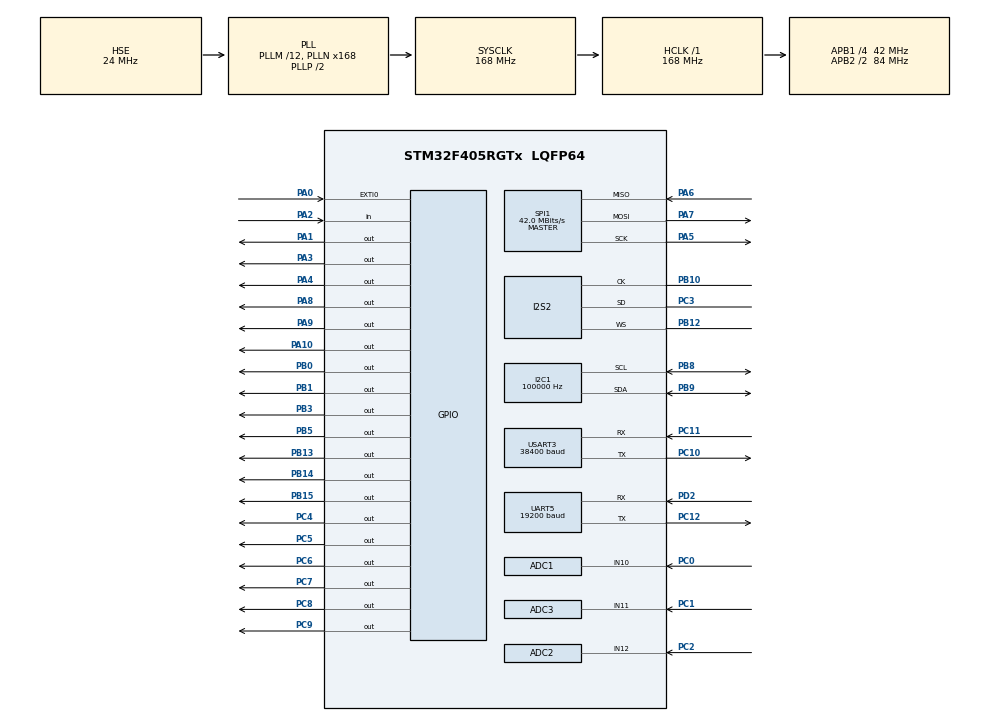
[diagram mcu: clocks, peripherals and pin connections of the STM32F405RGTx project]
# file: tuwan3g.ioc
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ADC1.Channel-0\#ChannelRegularConversion=ADC_CHANNEL_10
ADC1.ClockPrescaler=ADC_CLOCK_SYNC_PCLK_DIV4
ADC1.ContinuousConvMode=DISABLE
ADC1.DMAContinuousRequests=DISABLE
ADC1.DataAlign=ADC_DATAALIGN_RIGHT
ADC1.DiscontinuousConvMode=DISABLE
ADC1.EOCSelection=ADC_EOC_SINGLE_CONV
ADC1.EnableAnalogWatchDog=false
ADC1.ExternalTrigConvEdge=ADC_EXTERNALTRIGCONVEDGE_NONE
ADC1.InjNumberOfConversion=0
ADC1.NbrOfConversion=1
ADC1.NbrOfConversionFlag=1
ADC1.Rank-0\#ChannelRegularConversion=1
ADC1.Resolution=ADC_RESOLUTION_12B
ADC1.SamplingTime-0\#ChannelRegularConversion=ADC_SAMPLETIME_3CYCLES
ADC1.ScanConvMode=DISABLE
ADC1.master=1
ADC2.Channel-0\#ChannelRegularConversion=ADC_CHANNEL_12
ADC2.NbrOfConversionFlag=1
ADC2.Rank-0\#ChannelRegularConversion=1
ADC2.SamplingTime-0\#ChannelRegularConversion=ADC_SAMPLETIME_3CYCLES
ADC3.Channel-0\#ChannelRegularConversion=ADC_CHANNEL_11
ADC3.NbrOfConversionFlag=1
ADC3.Rank-0\#ChannelRegularConversion=1
ADC3.SamplingTime-0\#ChannelRegularConversion=ADC_SAMPLETIME_3CYCLES
Dma.Request0=SPI2_RX
Dma.Request1=USART3_TX
Dma.Request2=UART5_TX
Dma.SPI2_RX.0.Direction=DMA_PERIPH_TO_MEMORY
Dma.SPI2_RX.0.FIFOMode=DMA_FIFOMODE_DISABLE
Dma.SPI2_RX.0.Instance=DMA1_Stream3
Dma.SPI2_RX.0.MemDataAlignment=DMA_MDATAALIGN_HALFWORD
Dma.SPI2_RX.0.MemInc=DMA_MINC_ENABLE
Dma.SPI2_RX.0.Mode=DMA_CIRCULAR
Dma.SPI2_RX.0.PeriphDataAlignment=DMA_PDATAALIGN_HALFWORD
Dma.SPI2_RX.0.PeriphInc=DMA_PINC_DISABLE
Dma.SPI2_RX.0.Priority=DMA_PRIORITY_LOW
Dma.UART5_TX.2.Direction=DMA_MEMORY_TO_PERIPH
Dma.UART5_TX.2.FIFOMode=DMA_FIFOMODE_DISABLE
Dma.UART5_TX.2.Instance=DMA1_Stream7
Dma.UART5_TX.2.MemDataAlignment=DMA_MDATAALIGN_BYTE
Dma.UART5_TX.2.MemInc=DMA_MINC_ENABLE
Dma.UART5_TX.2.Mode=DMA_NORMAL
Dma.UART5_TX.2.PeriphDataAlignment=DMA_PDATAALIGN_BYTE
Dma.UART5_TX.2.PeriphInc=DMA_PINC_DISABLE
Dma.UART5_TX.2.Priority=DMA_PRIORITY_LOW
Dma.USART3_TX.1.Direction=DMA_MEMORY_TO_PERIPH
Dma.USART3_TX.1.FIFOMode=DMA_FIFOMODE_DISABLE
Dma.USART3_TX.1.Instance=DMA1_Stream4
Dma.USART3_TX.1.MemDataAlignment=DMA_MDATAALIGN_BYTE
Dma.USART3_TX.1.MemInc=DMA_MINC_ENABLE
Dma.USART3_TX.1.Mode=DMA_NORMAL
Dma.USART3_TX.1.PeriphDataAlignment=DMA_PDATAALIGN_BYTE
Dma.USART3_TX.1.PeriphInc=DMA_PINC_DISABLE
Dma.USART3_TX.1.Priority=DMA_PRIORITY_LOW
FREERTOS.Queues01=UART5Q,50,unsigned char,NULL;UART3Q,300,uint8_t,NULL
FREERTOS.Tasks01=MainTask,2,1000,MainTaskFunction,As weak;ForthTemialTask,-2,128,ForthTemialFunction,As weak;PositionTask,0,500,PositionTaskFunction,As weak;ActionTask,1,512,ActionTaskFunction,As weak;SnoreTask,0,1000,SnoreTaskFunction,As weak
FREERTOS.configTICK_RATE_HZ=1000
I2C1.ClockSpeed=100000
I2S2.AudioFreq=I2S_AUDIOFREQ_32K
I2S2.CPOL=I2S_CPOL_LOW
I2S2.ErrorAudioFreq=0.8 %
I2S2.Mode=I2S_MODE_MASTER_RX
I2S2.RealAudioFreq=32.258 KHz
I2S2.Standard=I2S_STANDARD_LSB
Mcu.Family=STM32F4
Mcu.Name=STM32F405RGTx
Mcu.Package=LQFP64
NVIC.ADC_IRQn=true\:0\:0\:false\:false\:true\:false
NVIC.DMA1_Stream3_IRQn=true\:6\:0\:true\:false\:true\:false
NVIC.DMA1_Stream4_IRQn=true\:5\:0\:false\:false\:true\:true
NVIC.DMA1_Stream7_IRQn=true\:5\:0\:false\:false\:true\:true
NVIC.EXTI0_IRQn=true\:5\:0\:false\:false\:true\:true
NVIC.PriorityGroup=NVIC_PRIORITYGROUP_4
NVIC.SPI1_IRQn=true\:0\:0\:false\:false\:true\:false
NVIC.SPI2_IRQn=true\:0\:0\:false\:false\:true\:false
NVIC.TIM6_DAC_IRQn=true\:0\:0\:false\:false\:true\:false
NVIC.TimeBase=TIM6_DAC_IRQn
NVIC.TimeBaseIP=TIM6
NVIC.UART5_IRQn=true\:5\:0\:false\:false\:true\:true
NVIC.USART3_IRQn=true\:5\:0\:true\:false\:true\:true
PA0-WKUP.Signal=GPXTI0
PA1.Signal=GPIO_Output
PA10.Signal=GPIO_Output
PA13.Mode=Serial_Wire
PA13.Signal=SYS_JTMS-SWDIO
PA14.Mode=Serial_Wire
PA14.Signal=SYS_JTCK-SWCLK
PA2.Signal=GPIO_Input
PA3.Signal=GPIO_Output
PA4.GPIO_Speed=GPIO_SPEED_FREQ_VERY_HIGH
PA4.PinState=GPIO_PIN_SET
PA4.Signal=GPIO_Output
PA5.GPIO_PuPd=GPIO_PULLUP
PA5.GPIO_Speed=GPIO_SPEED_FREQ_HIGH
PA5.Mode=Full_Duplex_Master
PA5.Signal=SPI1_SCK
PA6.GPIO_PuPd=GPIO_PULLUP
PA6.GPIO_Speed=GPIO_SPEED_FREQ_HIGH
PA6.Mode=Full_Duplex_Master
PA6.Signal=SPI1_MISO
PA7.GPIO_PuPd=GPIO_PULLUP
PA7.GPIO_Speed=GPIO_SPEED_FREQ_HIGH
PA7.Mode=Full_Duplex_Master
PA7.Signal=SPI1_MOSI
PA8.Signal=GPIO_Output
PA9.Signal=GPIO_Output
PB0.Signal=GPIO_Output
PB1.Signal=GPIO_Output
PB10.Mode=Half_Duplex_Master
PB10.Signal=I2S2_CK
PB12.Mode=Half_Duplex_Master
PB12.Signal=I2S2_WS
PB13.Signal=GPIO_Output
PB14.Signal=GPIO_Output
PB15.Signal=GPIO_Output
PB3.Signal=GPIO_Output
PB5.Signal=GPIO_Output
PB8.Mode=I2C
PB8.Signal=I2C1_SCL
PB9.Mode=I2C
PB9.Signal=I2C1_SDA
PC0.Signal=ADCx_IN10
PC1.Signal=ADCx_IN11
PC10.Mode=Asynchronous
PC10.Signal=USART3_TX
PC11.Mode=Asynchronous
PC11.Signal=USART3_RX
PC12.GPIO_Mode=GPIO_MODE_AF_PP
PC12.Mode=Asynchronous
PC12.Signal=UART5_TX
PC14-OSC32_IN.Mode=LSE-External-Oscillator
PC14-OSC32_IN.Signal=RCC_OSC32_IN
PC15-OSC32_OUT.Mode=LSE-External-Oscillator
PC15-OSC32_OUT.Signal=RCC_OSC32_OUT
PC2.Signal=ADCx_IN12
PC3.Mode=Half_Duplex_Master
PC3.Signal=I2S2_SD
PC4.Signal=GPIO_Output
PC5.Signal=GPIO_Output
PC6.Signal=GPIO_Output
PC7.Signal=GPIO_Output
PC8.Signal=GPIO_Output
PC9.Signal=GPIO_Output
PD2.Mode=Asynchronous
PD2.Signal=UART5_RX
PH0-OSC_IN.Mode=HSE-External-Oscillator
PH0-OSC_IN.Signal=RCC_OSC_IN
PH1-OSC_OUT.Mode=HSE-External-Oscillator
PH1-OSC_OUT.Signal=RCC_OSC_OUT
ProjectManager.HeapSize=0x900
ProjectManager.StackSize=0x2000
ProjectManager.TargetToolchain=MDK-ARM V5
RCC.48MHZClocksFreq_Value=84000000
RCC.AHBFreq_Value=168000000
RCC.APB1CLKDivider=RCC_HCLK_DIV4
RCC.APB1Freq_Value=42000000
RCC.APB1TimFreq_Value=84000000
RCC.APB2CLKDivider=RCC_HCLK_DIV2
RCC.APB2Freq_Value=84000000
RCC.APB2TimFreq_Value=168000000
RCC.CortexFreq_Value=168000000
RCC.HCLKFreq_Value=168000000
RCC.HSE_VALUE=24000000
RCC.HSI_VALUE=16000000
RCC.PLLI2SN=96
RCC.PLLI2SR=6
RCC.PLLM=12
RCC.PLLN=168
RCC.PLLSourceVirtual=RCC_PLLSOURCE_HSE
RCC.RCC_RTC_Clock_SourceVirtual=RCC_RTCCLKSOURCE_LSE
RCC.SYSCLKFreq_VALUE=168000000
RCC.SYSCLKSource=RCC_SYSCLKSOURCE_PLLCLK
RCC.VCOOutputFreq_Value=336000000
RTC.Hours=8
RTC.Seconds=10
SH.ADCx_IN10.0=ADC1_IN10,IN10
SH.ADCx_IN11.0=ADC3_IN11,IN11
SH.ADCx_IN12.0=ADC2_IN12,IN12
SPI1.BaudRatePrescaler=SPI_BAUDRATEPRESCALER_2
SPI1.CLKPhase=SPI_PHASE_2EDGE
SPI1.CLKPolarity=SPI_POLARITY_HIGH
SPI1.CalculateBaudRate=42.0 MBits/s
SPI1.Mode=SPI_MODE_MASTER
UART5.BaudRate=19200
USART3.BaudRate=38400
VP_FREERTOS_VS_ENABLE.Mode=Enabled
VP_RTC_VS_RTC_WakeUp_intern.Mode=WakeUp
VP_SYS_VS_tim6.Mode=TIM6
board=tuwan3g

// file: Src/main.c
/**
  ******************************************************************************
  * File Name          : main.c
  * Description        : Main program body
  ******************************************************************************
  *
  * COPYRIGHT(c) 2017 STMicroelectronics
  *
  * Redistribution and use in source and binary forms, with or without modification,
  * are permitted provided that the following conditions are met:
  *   1. Redistributions of source code must retain the above copyright notice,
  *      this list of conditions and the following disclaimer.
  *   2. Redistributions in binary form must reproduce the above copyright notice,
  *      this list of conditions and the following disclaimer in the documentation
  *      and/or other materials provided with the distribution.
  *   3. Neither the name of STMicroelectronics nor the names of its contributors
  *      may be used to endorse or promote products derived from this software
  *      without specific prior written permission.
  *
  * THIS SOFTWARE IS PROVIDED BY THE COPYRIGHT HOLDERS AND CONTRIBUTORS "AS IS"
  * AND ANY EXPRESS OR IMPLIED WARRANTIES, INCLUDING, BUT NOT LIMITED TO, THE
  * IMPLIED WARRANTIES OF MERCHANTABILITY AND FITNESS FOR A PARTICULAR PURPOSE ARE
  * DISCLAIMED. IN NO EVENT SHALL THE COPYRIGHT HOLDER OR CONTRIBUTORS BE LIABLE
  * FOR ANY DIRECT, INDIRECT, INCIDENTAL, SPECIAL, EXEMPLARY, OR CONSEQUENTIAL
  * DAMAGES (INCLUDING, BUT NOT LIMITED TO, PROCUREMENT OF SUBSTITUTE GOODS OR
  * SERVICES; LOSS OF USE, DATA, OR PROFITS; OR BUSINESS INTERRUPTION) HOWEVER
  * CAUSED AND ON ANY THEORY OF LIABILITY, WHETHER IN CONTRACT, STRICT LIABILITY,
  * OR TORT (INCLUDING NEGLIGENCE OR OTHERWISE) ARISING IN ANY WAY OUT OF THE USE
  * OF THIS SOFTWARE, EVEN IF ADVISED OF THE POSSIBILITY OF SUCH DAMAGE.
  *
  ******************************************************************************
  */
#include "stm32f4xx_hal.h"
#include "cmsis_os.h"

/* USER CODE BEGIN Includes */
#include "W25Q16.h"
#include "tuwan.h"
/* USER CODE END Includes */

ADC_HandleTypeDef hadc1;
ADC_HandleTypeDef hadc2;
ADC_HandleTypeDef hadc3;

I2C_HandleTypeDef hi2c1;

I2S_HandleTypeDef hi2s2;
DMA_HandleTypeDef hdma_spi2_rx;

RTC_HandleTypeDef hrtc;

SPI_HandleTypeDef hspi1;

UART_HandleTypeDef huart5;
UART_HandleTypeDef huart3;
DMA_HandleTypeDef hdma_uart5_tx;
DMA_HandleTypeDef hdma_usart3_tx;

osThreadId MainTaskHandle;
osThreadId ForthTemialTaskHandle;
osThreadId PositionTaskHandle;
osThreadId ActionTaskHandle;
osThreadId SnoreTaskHandle;
osMessageQId UART5QHandle;
osMessageQId UART3QHandle;

/* USER CODE BEGIN PV */
xQueueHandle  ExhalAdcQHandle,InhalAdcQHandle;
/* Private variables ---------------------------------------------------------*/
/* USER CODE END PV */

void SystemClock_Config(void);
void Error_Handler(void);
static void MX_GPIO_Init(void);
static void MX_DMA_Init(void);
static void MX_I2C1_Init(void);
static void MX_I2S2_Init(void);
static void MX_SPI1_Init(void);
static void MX_UART5_Init(void);
static void MX_USART3_UART_Init(void);
static void MX_ADC1_Init(void);
static void MX_ADC2_Init(void);
static void MX_RTC_Init(void);
static void MX_ADC3_Init(void);
void MainTaskFunction(void const * argument);
void ForthTemialFunction(void const * argument);
void PositionTaskFunction(void const * argument);
void ActionTaskFunction(void const * argument);
void SnoreTaskFunction(void const * argument);

/* USER CODE BEGIN PFP */
/* Private function prototypes -----------------------------------------------*/

/* USER CODE END PFP */

int main(void)
{

  /* MCU Configuration----------------------------------------------------------*/

  /* Reset of all peripherals, Initializes the Flash interface and the Systick. */
  HAL_Init();

  /* Configure the system clock */
  SystemClock_Config();

  /* Initialize all configured peripherals */
  MX_GPIO_Init();
  MX_DMA_Init();
#ifndef SOFTIIC
  MX_I2C1_Init();
#endif
  MX_I2S2_Init();
  MX_SPI1_Init();
  MX_UART5_Init();
  MX_USART3_UART_Init();
  MX_ADC1_Init();
  MX_ADC2_Init();
  MX_RTC_Init();
  MX_ADC3_Init();

  /* USER CODE BEGIN 2 */
  FLASH_SPI_CS_DISABLE();
	__set_PRIMASK(0);
	//CheckSystemParameter(); //disabled by zjp for no bootloader
	InhalePump(0);
	ExhalePump(0);

	BlueToolthEnabled(0);
	ERP_ON();
	/// BlueToolLed(1);
	 ErrorCode=0;

	 PowerLed(1);
	 RunLed(1);
	 /*
	 ResetValuePump();

	 EntryStandbyMode();
	*/
  // while(1);

	 /*
	 while(1)
	 {
	 d=10000000;
	 PowerLed(0);
	 while(d--);
		  d=10000000;
	 PowerLed(1);
	 while(d--);

	 }
	 */

  /* USER CODE END 2 */

  /* Create the thread(s) */
  /* definition and creation of MainTask */
  osThreadDef(MainTask, MainTaskFunction, osPriorityNormal, 0, 1100);
  MainTaskHandle = osThreadCreate(osThread(MainTask), NULL);

  /* definition and creation of ForthTemialTask */
  osThreadDef(ForthTemialTask, ForthTemialFunction, osPriorityLow, 0, 128);
  ForthTemialTaskHandle = osThreadCreate(osThread(ForthTemialTask), NULL);

  /* definition and creation of PositionTask */
  osThreadDef(PositionTask, PositionTaskFunction, osPriorityBelowNormal, 0, 500);
  PositionTaskHandle = osThreadCreate(osThread(PositionTask), NULL);

  /* definition and creation of ActionTask */
  osThreadDef(ActionTask, ActionTaskFunction, osPriorityLow, 0, 512);
  ActionTaskHandle = osThreadCreate(osThread(ActionTask), NULL);

  /* definition and creation of SnoreTask */
  osThreadDef(SnoreTask, SnoreTaskFunction, osPriorityHigh, 0, 1000);
  SnoreTaskHandle = osThreadCreate(osThread(SnoreTask), NULL);

  /* Create the queue(s) */
  /* definition and creation of UART5Q */
  osMessageQDef(UART5Q, 50, unsigned char);
  UART5QHandle = osMessageCreate(osMessageQ(UART5Q), NULL);

  /* definition and creation of UART3Q */
  osMessageQDef(UART3Q, 300, uint8_t);
  UART3QHandle = osMessageCreate(osMessageQ(UART3Q), NULL);

  /* USER CODE BEGIN RTOS_QUEUES */
  /* add queues, ... */
  ExhalAdcQHandle = xQueueCreate( 10 , sizeof( unsigned int) );
	InhalAdcQHandle = xQueueCreate( 10 , sizeof( unsigned int) );
  /* USER CODE END RTOS_QUEUES */

  /* Start scheduler */
  osKernelStart();

  /* We should never get here as control is now taken by the scheduler */

  /* Infinite loop */
  while (1)
  {

  }

}

/** System Clock Configuration
*/
void SystemClock_Config(void)
{

  RCC_OscInitTypeDef RCC_OscInitStruct;
  RCC_ClkInitTypeDef RCC_ClkInitStruct;
  RCC_PeriphCLKInitTypeDef PeriphClkInitStruct;

  __HAL_RCC_PWR_CLK_ENABLE();

  __HAL_PWR_VOLTAGESCALING_CONFIG(PWR_REGULATOR_VOLTAGE_SCALE1);

  RCC_OscInitStruct.OscillatorType = RCC_OSCILLATORTYPE_HSE|RCC_OSCILLATORTYPE_LSE;
  RCC_OscInitStruct.HSEState = RCC_HSE_ON;
  RCC_OscInitStruct.LSEState = RCC_LSE_ON;
  RCC_OscInitStruct.PLL.PLLState = RCC_PLL_ON;
  RCC_OscInitStruct.PLL.PLLSource = RCC_PLLSOURCE_HSE;
  RCC_OscInitStruct.PLL.PLLM = 12;
  RCC_OscInitStruct.PLL.PLLN = 168;
  RCC_OscInitStruct.PLL.PLLP = RCC_PLLP_DIV2;
  RCC_OscInitStruct.PLL.PLLQ = 4;
  if (HAL_RCC_OscConfig(&RCC_OscInitStruct) != HAL_OK)
  {
    Error_Handler();
  }

  RCC_ClkInitStruct.ClockType = RCC_CLOCKTYPE_HCLK|RCC_CLOCKTYPE_SYSCLK
                              |RCC_CLOCKTYPE_PCLK1|RCC_CLOCKTYPE_PCLK2;
  RCC_ClkInitStruct.SYSCLKSource = RCC_SYSCLKSOURCE_PLLCLK;
  RCC_ClkInitStruct.AHBCLKDivider = RCC_SYSCLK_DIV1;
  RCC_ClkInitStruct.APB1CLKDivider = RCC_HCLK_DIV4;
  RCC_ClkInitStruct.APB2CLKDivider = RCC_HCLK_DIV2;
  if (HAL_RCC_ClockConfig(&RCC_ClkInitStruct, FLASH_LATENCY_5) != HAL_OK)
  {
    Error_Handler();
  }

  PeriphClkInitStruct.PeriphClockSelection = RCC_PERIPHCLK_I2S|RCC_PERIPHCLK_RTC;
  PeriphClkInitStruct.PLLI2S.PLLI2SN = 96;
  PeriphClkInitStruct.PLLI2S.PLLI2SR = 6;
  PeriphClkInitStruct.RTCClockSelection = RCC_RTCCLKSOURCE_LSE;
  if (HAL_RCCEx_PeriphCLKConfig(&PeriphClkInitStruct) != HAL_OK)
  {
    Error_Handler();
  }

  HAL_SYSTICK_Config(HAL_RCC_GetHCLKFreq()/1000);

  HAL_SYSTICK_CLKSourceConfig(SYSTICK_CLKSOURCE_HCLK);

  /* SysTick_IRQn interrupt configuration */
  HAL_NVIC_SetPriority(SysTick_IRQn, 15, 0);
}

/* ADC1 init function */
static void MX_ADC1_Init(void)
{

  ADC_ChannelConfTypeDef sConfig;

    /**Configure the global features of the ADC (Clock, Resolution, Data Alignment and number of conversion)
    */
  hadc1.Instance = ADC1;
  hadc1.Init.ClockPrescaler = ADC_CLOCK_SYNC_PCLK_DIV4;
  hadc1.Init.Resolution = ADC_RESOLUTION_12B;
  hadc1.Init.ScanConvMode = DISABLE;
  hadc1.Init.ContinuousConvMode = DISABLE;
  hadc1.Init.DiscontinuousConvMode = DISABLE;
  hadc1.Init.ExternalTrigConvEdge = ADC_EXTERNALTRIGCONVEDGE_NONE;
  hadc1.Init.DataAlign = ADC_DATAALIGN_RIGHT;
  hadc1.Init.NbrOfConversion = 1;
  hadc1.Init.DMAContinuousRequests = DISABLE;
  hadc1.Init.EOCSelection = ADC_EOC_SINGLE_CONV;
  if (HAL_ADC_Init(&hadc1) != HAL_OK)
  {
    Error_Handler();
  }

    /**Configure for the selected ADC regular channel its corresponding rank in the sequencer and its sample time.
    */
  sConfig.Channel = ADC_CHANNEL_10;
  sConfig.Rank = 1;
  sConfig.SamplingTime = ADC_SAMPLETIME_3CYCLES;
  if (HAL_ADC_ConfigChannel(&hadc1, &sConfig) != HAL_OK)
  {
    Error_Handler();
  }

}

/* ADC2 init function */
static void MX_ADC2_Init(void)
{

  ADC_ChannelConfTypeDef sConfig;

    /**Configure the global features of the ADC (Clock, Resolution, Data Alignment and number of conversion)
    */
  hadc2.Instance = ADC2;
  hadc2.Init.ClockPrescaler = ADC_CLOCK_SYNC_PCLK_DIV4;
  hadc2.Init.Resolution = ADC_RESOLUTION_12B;
  hadc2.Init.ScanConvMode = DISABLE;
  hadc2.Init.ContinuousConvMode = DISABLE;
  hadc2.Init.DiscontinuousConvMode = DISABLE;
  hadc2.Init.ExternalTrigConvEdge = ADC_EXTERNALTRIGCONVEDGE_NONE;
  hadc2.Init.DataAlign = ADC_DATAALIGN_RIGHT;
  hadc2.Init.NbrOfConversion = 1;
  hadc2.Init.DMAContinuousRequests = DISABLE;
  hadc2.Init.EOCSelection = ADC_EOC_SINGLE_CONV;
  if (HAL_ADC_Init(&hadc2) != HAL_OK)
  {
    Error_Handler();
  }

    /**Configure for the selected ADC regular channel its corresponding rank in the sequencer and its sample time.
    */
  sConfig.Channel = ADC_CHANNEL_12;
  sConfig.Rank = 1;
  sConfig.SamplingTime = ADC_SAMPLETIME_3CYCLES;
  if (HAL_ADC_ConfigChannel(&hadc2, &sConfig) != HAL_OK)
  {
    Error_Handler();
  }

}

/* ADC3 init function */
static void MX_ADC3_Init(void)
{

  ADC_ChannelConfTypeDef sConfig;

    /**Configure the global features of the ADC (Clock, Resolution, Data Alignment and number of conversion)
    */
  hadc3.Instance = ADC3;
  hadc3.Init.ClockPrescaler = ADC_CLOCK_SYNC_PCLK_DIV4;
  hadc3.Init.Resolution = ADC_RESOLUTION_12B;
  hadc3.Init.ScanConvMode = DISABLE;
  hadc3.Init.ContinuousConvMode = DISABLE;
  hadc3.Init.DiscontinuousConvMode = DISABLE;
  hadc3.Init.ExternalTrigConvEdge = ADC_EXTERNALTRIGCONVEDGE_NONE;
  hadc3.Init.DataAlign = ADC_DATAALIGN_RIGHT;
  hadc3.Init.NbrOfConversion = 1;
  hadc3.Init.DMAContinuousRequests = DISABLE;
  hadc3.Init.EOCSelection = ADC_EOC_SINGLE_CONV;
  if (HAL_ADC_Init(&hadc3) != HAL_OK)
  {
    Error_Handler();
  }

    /**Configure for the selected ADC regular channel its corresponding rank in the sequencer and its sample time.
    */
  sConfig.Channel = ADC_CHANNEL_11; //气压传感器采样
  sConfig.Rank = 1;
  sConfig.SamplingTime = ADC_SAMPLETIME_3CYCLES;
  if (HAL_ADC_ConfigChannel(&hadc3, &sConfig) != HAL_OK)
  {
    Error_Handler();
  }

}

/* I2C1 init function */
extern void MX_I2C1_Init(void)
{

  hi2c1.Instance = I2C1;
  hi2c1.Init.ClockSpeed = 100000;
  hi2c1.Init.DutyCycle = I2C_DUTYCYCLE_2;
  hi2c1.Init.OwnAddress1 = 0;
  hi2c1.Init.AddressingMode = I2C_ADDRESSINGMODE_7BIT;
  hi2c1.Init.DualAddressMode = I2C_DUALADDRESS_DISABLE;
  hi2c1.Init.OwnAddress2 = 0;
  hi2c1.Init.GeneralCallMode = I2C_GENERALCALL_DISABLE;
  hi2c1.Init.NoStretchMode = I2C_NOSTRETCH_DISABLE;
  if (HAL_I2C_Init(&hi2c1) != HAL_OK)
  {
    Error_Handler();
  }

}

/* I2S2 init function */
static void MX_I2S2_Init(void)
{

  hi2s2.Instance = SPI2;
  hi2s2.Init.Mode = I2S_MODE_MASTER_RX;
  hi2s2.Init.Standard = I2S_STANDARD_LSB;
  hi2s2.Init.DataFormat = I2S_DATAFORMAT_16B;
  hi2s2.Init.MCLKOutput = I2S_MCLKOUTPUT_DISABLE;
  hi2s2.Init.AudioFreq = I2S_AUDIOFREQ_32K;
  hi2s2.Init.CPOL = I2S_CPOL_LOW;
  hi2s2.Init.ClockSource = I2S_CLOCK_PLL;
  hi2s2.Init.FullDuplexMode = I2S_FULLDUPLEXMODE_DISABLE;
  if (HAL_I2S_Init(&hi2s2) != HAL_OK)
  {
    Error_Handler();
  }

}

/* RTC init function */
static void MX_RTC_Init(void)
{

  //RTC_TimeTypeDef sTime;
  //RTC_DateTypeDef sDate;

    /**Initialize RTC and set the Time and Date
    */
  hrtc.Instance = RTC;
  hrtc.Init.HourFormat = RTC_HOURFORMAT_24;
  hrtc.Init.AsynchPrediv = 127;
  hrtc.Init.SynchPrediv = 255;
  hrtc.Init.OutPut = RTC_OUTPUT_DISABLE;
  hrtc.Init.OutPutPolarity = RTC_OUTPUT_POLARITY_HIGH;
  hrtc.Init.OutPutType = RTC_OUTPUT_TYPE_OPENDRAIN;
  if (HAL_RTC_Init(&hrtc) != HAL_OK)
  {
    Error_Handler();
  }
/*
  sTime.Hours = 0x8;
  sTime.Minutes = 0x0;
  sTime.Seconds = 0x10;
  sTime.DayLightSaving = RTC_DAYLIGHTSAVING_NONE;
  sTime.StoreOperation = RTC_STOREOPERATION_RESET;
  if (HAL_RTC_SetTime(&hrtc, &sTime, RTC_FORMAT_BCD) != HAL_OK)
  {
    Error_Handler();
  }

  sDate.WeekDay = RTC_WEEKDAY_MONDAY;
  sDate.Month = RTC_MONTH_JANUARY;
  sDate.Date = 0x1;
  sDate.Year = 0x0;

  if (HAL_RTC_SetDate(&hrtc, &sDate, RTC_FORMAT_BCD) != HAL_OK)
  {
    Error_Handler();
  }
*/
    /**Enable the WakeUp
    */
  if (HAL_RTCEx_SetWakeUpTimer(&hrtc, 0, RTC_WAKEUPCLOCK_RTCCLK_DIV16) != HAL_OK)
  {
    Error_Handler();
  }

}

/* SPI1 init function */
static void MX_SPI1_Init(void)
{

  hspi1.Instance = SPI1;
  hspi1.Init.Mode = SPI_MODE_MASTER;
  hspi1.Init.Direction = SPI_DIRECTION_2LINES;
  hspi1.Init.DataSize = SPI_DATASIZE_8BIT;
  hspi1.Init.CLKPolarity = SPI_POLARITY_HIGH;
  hspi1.Init.CLKPhase = SPI_PHASE_2EDGE;
  hspi1.Init.NSS = SPI_NSS_SOFT;
  hspi1.Init.BaudRatePrescaler = SPI_BAUDRATEPRESCALER_2;
  hspi1.Init.FirstBit = SPI_FIRSTBIT_MSB;
  hspi1.Init.TIMode = SPI_TIMODE_DISABLE;
  hspi1.Init.CRCCalculation = SPI_CRCCALCULATION_DISABLE;
  hspi1.Init.CRCPolynomial = 10;
  if (HAL_SPI_Init(&hspi1) != HAL_OK)
  {
    Error_Handler();
  }

}

/* UART5 init function */
static void MX_UART5_Init(void)
{

  huart5.Instance = UART5;
  huart5.Init.BaudRate = UART5_BAUDRATE;//115200;
  huart5.Init.WordLength = UART_WORDLENGTH_8B;
  huart5.Init.StopBits = UART_STOPBITS_1;
  huart5.Init.Parity = UART_PARITY_NONE;
  huart5.Init.Mode = UART_MODE_TX_RX;
  huart5.Init.HwFlowCtl = UART_HWCONTROL_NONE;
  huart5.Init.OverSampling = UART_OVERSAMPLING_16;
  if (HAL_UART_Init(&huart5) != HAL_OK)
  {
    Error_Handler();
  }

}

/* USART3 init function */
static void MX_USART3_UART_Init(void)
{

  huart3.Instance = USART3;
  huart3.Init.BaudRate = 38400;
  huart3.Init.WordLength = UART_WORDLENGTH_8B;
  huart3.Init.StopBits = UART_STOPBITS_1;
  huart3.Init.Parity = UART_PARITY_NONE;
  huart3.Init.Mode = UART_MODE_TX_RX;
  huart3.Init.HwFlowCtl = UART_HWCONTROL_NONE;
  huart3.Init.OverSampling = UART_OVERSAMPLING_16;
  if (HAL_UART_Init(&huart3) != HAL_OK)
  {
    Error_Handler();
  }

}

static void MX_DMA_Init(void)
{
  /* DMA controller clock enable */
  __HAL_RCC_DMA1_CLK_ENABLE();

  /* DMA interrupt init */
  /* DMA1_Stream3_IRQn interrupt configuration */
  HAL_NVIC_SetPriority(DMA1_Stream3_IRQn, 6, 0);
  HAL_NVIC_EnableIRQ(DMA1_Stream3_IRQn);
  /* DMA1_Stream4_IRQn interrupt configuration */
  HAL_NVIC_SetPriority(DMA1_Stream4_IRQn, 5, 0);
  HAL_NVIC_EnableIRQ(DMA1_Stream4_IRQn);
  /* DMA1_Stream7_IRQn interrupt configuration */
  HAL_NVIC_SetPriority(DMA1_Stream7_IRQn, 5, 0);
  HAL_NVIC_EnableIRQ(DMA1_Stream7_IRQn);

}

/** Configure pins as
        * Analog
        * Input
        * Output
        * EVENT_OUT
        * EXTI
*/
static void MX_GPIO_Init(void)
{

  GPIO_InitTypeDef GPIO_InitStruct;

  /* GPIO Ports Clock Enable */
  __HAL_RCC_GPIOC_CLK_ENABLE();
  __HAL_RCC_GPIOH_CLK_ENABLE();
  __HAL_RCC_GPIOA_CLK_ENABLE();
  __HAL_RCC_GPIOB_CLK_ENABLE();
  __HAL_RCC_GPIOD_CLK_ENABLE();

  /*Configure GPIO pin : PA0 */
  GPIO_InitStruct.Pin = GPIO_PIN_0;
  GPIO_InitStruct.Mode = GPIO_MODE_IT_RISING;
  GPIO_InitStruct.Pull = GPIO_NOPULL;
  HAL_GPIO_Init(GPIOA, &GPIO_InitStruct);

  /*Configure GPIO pins : PA1 PA3 PA8 PA9
                           PA10 */
  GPIO_InitStruct.Pin = GPIO_PIN_1|GPIO_PIN_3|GPIO_PIN_8|GPIO_PIN_9
                          |GPIO_PIN_10;
  GPIO_InitStruct.Mode = GPIO_MODE_OUTPUT_PP;
  GPIO_InitStruct.Pull = GPIO_NOPULL;
  GPIO_InitStruct.Speed = GPIO_SPEED_FREQ_LOW;
  HAL_GPIO_Init(GPIOA, &GPIO_InitStruct);

  /*Configure GPIO pin : PA2 */
  GPIO_InitStruct.Pin = GPIO_PIN_2;
  GPIO_InitStruct.Mode = GPIO_MODE_INPUT;
  GPIO_InitStruct.Pull = GPIO_NOPULL;
  HAL_GPIO_Init(GPIOA, &GPIO_InitStruct);

  /*Configure GPIO pin : PA4 */
  GPIO_InitStruct.Pin = GPIO_PIN_4;
  GPIO_InitStruct.Mode = GPIO_MODE_OUTPUT_PP;
  GPIO_InitStruct.Pull = GPIO_NOPULL;
  GPIO_InitStruct.Speed = GPIO_SPEED_FREQ_VERY_HIGH;
  HAL_GPIO_Init(GPIOA, &GPIO_InitStruct);

  /*Configure GPIO pins : PB0 PB1 PB13 PB14
                           PB15 PB3 PB5 */
  GPIO_InitStruct.Pin = GPIO_PIN_0|GPIO_PIN_1|GPIO_PIN_13|GPIO_PIN_14
                          |GPIO_PIN_15|GPIO_PIN_3|GPIO_PIN_4|GPIO_PIN_5;
  GPIO_InitStruct.Mode = GPIO_MODE_OUTPUT_PP;
  GPIO_InitStruct.Pull = GPIO_NOPULL;
  GPIO_InitStruct.Speed = GPIO_SPEED_FREQ_LOW;
  HAL_GPIO_Init(GPIOB, &GPIO_InitStruct);

  /*Configure GPIO pins : PC6 PC7 PC8 PC9 */
  GPIO_InitStruct.Pin = GPIO_PIN_4|GPIO_PIN_5|GPIO_PIN_6|GPIO_PIN_7|GPIO_PIN_8|GPIO_PIN_9;
  GPIO_InitStruct.Mode = GPIO_MODE_OUTPUT_PP;
  GPIO_InitStruct.Pull = GPIO_NOPULL;
  GPIO_InitStruct.Speed = GPIO_SPEED_FREQ_LOW;
  HAL_GPIO_Init(GPIOC, &GPIO_InitStruct);

  /*Configure GPIO pin Output Level */
  HAL_GPIO_WritePin(GPIOA, GPIO_PIN_1|GPIO_PIN_3|GPIO_PIN_8|GPIO_PIN_9
                          |GPIO_PIN_10, GPIO_PIN_RESET);

  /*Configure GPIO pin Output Level */
  HAL_GPIO_WritePin(GPIOA, GPIO_PIN_4, GPIO_PIN_SET);

  /*Configure GPIO pin Output Level */
  HAL_GPIO_WritePin(GPIOB, GPIO_PIN_0|GPIO_PIN_1|GPIO_PIN_13|GPIO_PIN_14
                          |GPIO_PIN_15|GPIO_PIN_3|GPIO_PIN_5, GPIO_PIN_RESET);

  /*Configure GPIO pin Output Level */
  HAL_GPIO_WritePin(GPIOC, GPIO_PIN_6|GPIO_PIN_7|GPIO_PIN_8|GPIO_PIN_9, GPIO_PIN_RESET);

	/*Configure GPIO pins : PB8 PB9 */
  GPIO_InitStruct.Pin = GPIO_PIN_8|GPIO_PIN_9;
  GPIO_InitStruct.Mode = GPIO_MODE_OUTPUT_PP;
  GPIO_InitStruct.Pull = GPIO_PULLUP;
  GPIO_InitStruct.Speed = GPIO_SPEED_FREQ_VERY_HIGH;
  HAL_GPIO_Init(GPIOB, &GPIO_InitStruct);

  /* EXTI interrupt init*/
  HAL_NVIC_SetPriority(EXTI0_IRQn, 5, 0);
  HAL_NVIC_EnableIRQ(EXTI0_IRQn);

}

/* MainTaskFunction function */
__weak void MainTaskFunction(void const * argument)
{

  /* USER CODE BEGIN 5 */
  /* Infinite loop */
  for(;;)
  {
    osDelay(10);
  }
  /* USER CODE END 5 */
}

/* ForthTemialFunction function */
__weak void ForthTemialFunction(void const * argument)
{
  /* USER CODE BEGIN ForthTemialFunction */
  /* Infinite loop */
  for(;;)
  {
    osDelay(10);
  }
  /* USER CODE END ForthTemialFunction */
}

/* PositionTaskFunction function */
__weak void PositionTaskFunction(void const * argument)
{
  /* USER CODE BEGIN PositionTaskFunction */
  /* Infinite loop */
  for(;;)
  {
    osDelay(10);
  }
  /* USER CODE END PositionTaskFunction */
}

/* ActionTaskFunction function */
__weak void ActionTaskFunction(void const * argument)
{
  /* USER CODE BEGIN ActionTaskFunction */
  /* Infinite loop */
  for(;;)
  {
    osDelay(10);
  }
  /* USER CODE END ActionTaskFunction */
}

/* SnoreTaskFunction function */
__weak void SnoreTaskFunction(void const * argument)
{
  /* USER CODE BEGIN SnoreTaskFunction */
  /* Infinite loop */
  for(;;)
  {
    osDelay(10);
  }
  /* USER CODE END SnoreTaskFunction */
}

void HAL_TIM_PeriodElapsedCallback(TIM_HandleTypeDef *htim)
{
  if (htim->Instance == TIM6) {
    HAL_IncTick();
  }
}

void Error_Handler(void)
{
  while(1)
  {
  }
}

/************************ (C) COPYRIGHT STMicroelectronics *****END OF FILE****/
